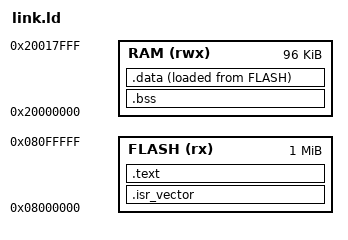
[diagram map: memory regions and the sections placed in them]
/* NUCLEO-L476RG: 1 MiB flash, 96 KiB SRAM1. */
MEMORY
{
  FLASH (rx)  : ORIGIN = 0x08000000, LENGTH = 1024K
  RAM   (rwx) : ORIGIN = 0x20000000, LENGTH = 96K
}
_estack = ORIGIN(RAM) + LENGTH(RAM);
SECTIONS
{
  .isr_vector : { KEEP(*(.isr_vector)) } > FLASH
  .text : { *(.text*) *(.rodata*) } > FLASH
  .bss (NOLOAD) : { *(.bss*) *(COMMON) } > RAM
  .data : { *(.data*) } > RAM AT > FLASH
}
